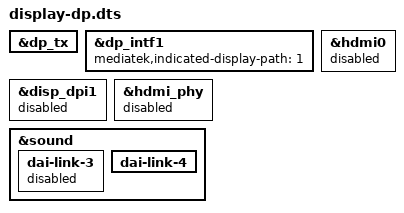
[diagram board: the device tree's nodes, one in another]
/dts-v1/;
/plugin/;

/ {
	fragment@0 {
		target = <&dp_tx>;
		__overlay__ {
			status = "okay";
		};
	};

	fragment@1 {
		target = <&dp_intf1>;
		__overlay__ {
			status = "okay";
			mediatek,indicated-display-path = <1>;
		};
	};

	fragment@2 {
		target = <&disp_dpi1>;
		__overlay__ {
			status = "disabled";
		};
	};

	fragment@3 {
		target = <&hdmi0>;
		__overlay__ {
			status = "disabled";
		};
	};

	fragment@4 {
		target = <&hdmi_phy>;
		__overlay__ {
			status = "disabled";
		};
	};

	fragment@5 {
		target = <&sound>;
		__overlay__ {
			dai-link-3 { /* HDMI */
				status = "disabled";
			};

			dai-link-4 { /* DPTX */
				status = "okay";
			};
		};
	};
};
